# K1921VG1T register map
Vendor: NIIET; Series: K1921VGx; File version: 2.8
CPU: other r0p1, little endian, MPU, FPU, 4 interrupt priority bits
Registers are 32-bit, read-write, reset 0x0 unless marked. A register's access mark holds for its fields unless they carry their own. Offsets are from the block's base; [hi:lo] are bit positions; lines under a group give offsets from that group; {n}, {i} and the like mark numbered series.

## MSC — MSC control registers
Base 0x5201C000
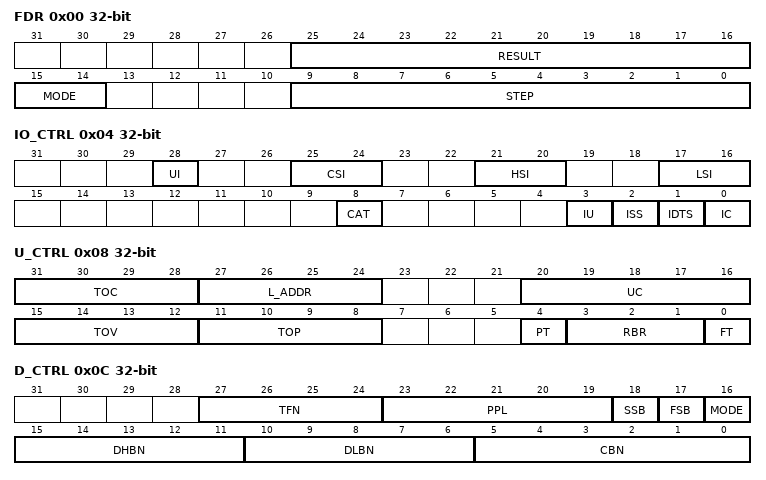
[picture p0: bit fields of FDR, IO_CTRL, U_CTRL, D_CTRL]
0x00 FDR — Fractional divider register
  [25:16] RESULT ro — Count frequency divider
  [15:14] MODE — Mode setting of the frequency divider
    0=TURN_OFF (Divider is turned off. Fmsc isn't generated); 1=NORMAL (Normal divider mod is selected); 2=FRACTIONAL (Fractional divider mode is selected); 3=BYPASS (Bypass mode is selected (Fmsc = Fapb / 2))
  [9:0] STEP — Divider start value in the normal mode / Step of divider in the fractional mode
0x04 IO_CTRL — Input/output Control Register
  [28] UI — Upstream input Index
  [25:24] CSI — Command Slave Index
  [21:20] HSI — High data part Slave Index
  [17:16] LSI — Low data part Slave Index
  [8] CAT — Clock All Time
  [3] IU — Invert Upstream input
  [2] ISS — Invert Slave Select output
  [1] IDTS — Invert Data To Slave output
  [0] IC — Invert Clock output
0x08 U_CTRL — Upstream Control/Status Register
  [31:28] TOC ro — Upstream time out timer counter current value
  [27:24] L_ADDR ro — Last received frame address
  [20:16] UC ro — Upstream bits down counter
  [15:12] TOV — Upstream time out timer restart value
  [11:8] TOP — Upstream time out timer prescaler of receive baud rate frequency (Fbr)
    0=TURN_OFF (Upstream timer prescaler disabled); 1=DIV1 (Fbr/1); 2=DIV2 (Fbr/2); 3=DIV4 (Fbr/4); 4=DIV8 (Fbr/8); 5=DIV16 (Fbr/16); 6=DIV32 (Fbr/32); 7=DIV64 (Fbr/64); 8=DIV128 (Fbr/128); 9=DIV256 (Fbr/256); 10=DIV512 (Fbr/512); 11=DIV1024 (Fbr/1024); 12=DIV2048 (Fbr/2048); 13=DIV4096 (Fbr/4096); 14=DIV8192 (Fbr/8192); 15=DIV16384 (Fbr/16384)
  [4] PT — Parity type (0 - Even parity; 1 - Odd parity)
    0=EVEN (Even parity mode - a parity bit is set on an odd number of 1s in the serial address/data stream); 1=ODD (Odd parity mode - a parity bit is set on an even number of 1s in the serial address/data stream)
  [3:1] RBR — Upstream Channel Receiving Rate
    0=TURN_OFF (Upstream channel disabled); 1=DIV4 (Baud rate = Fmsc/4); 2=DIV8 (Baud rate = Fmsc/8); 3=DIV16 (Baud rate = Fmsc/16); 4=DIV32 (4Baud rate = Fmsc/32); 5=DIV64 (Baud rate = Fmsc/64); 6=DIV128 (Baud rate = Fmsc/128); 7=DIV256 (Baud rate = Fmsc/256)
  [0] FT — Upstream Frame Type (0 - 12-bit; 1 - 16bit)
    0=FRAME_12 (Upstream without 4-bit address field); 1=FRAME_16 (full length 16-bit upstream frame)
0x0C D_CTRL — Downstream Control Register
  [27:24] TFN — passive Time Frames Number
  [23:19] PPL — Passive Phase Length (data/time frame)
  [18] SSB — Second Selection Bit (data/time frame)
  [17] FSB — First Selection Bit (data/time frame)
  [16] MODE — transmission Mode (0 - Triggered; 1 - Data repetition)
    0=TRIGGERED (Triggered mode selected); 1=DATAREPETITION (Data repetition mode selected)
  [15:11] DHBN — Data High Bits Number
  [10:6] DLBN — Data Low Bits Number
  [5:0] CBN — Command Bits Number
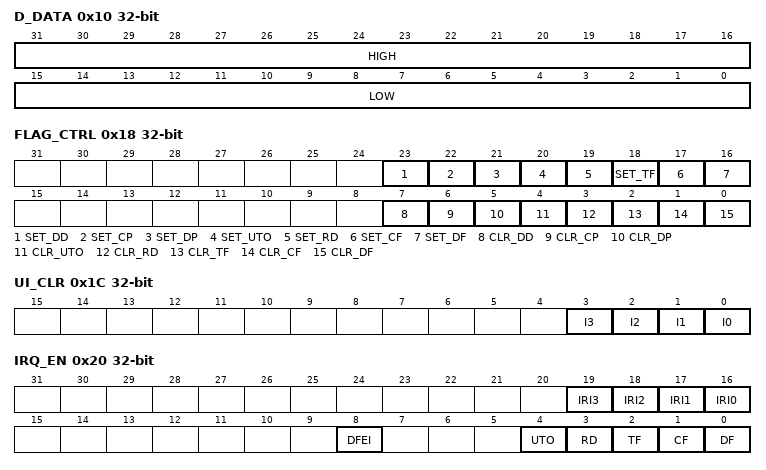
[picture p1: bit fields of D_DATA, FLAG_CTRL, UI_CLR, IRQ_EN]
0x10 D_DATA — Downstream Data bits
  [31:16] HIGH, [15:0] LOW
0x14 D_CMD — Downstream Command bits
  [31:0] VAL
0x18 FLAG_CTRL wo — Flags control register (set/clear)
  [23] SET_DD — Set Downstream Disabled flag
  [22] SET_CP — vCommand pending flag
  [21] SET_DP — Set Data Pending flag
  [20] SET_UTO — Set Upstream Time-Out flag
  [19] SET_RD — Set Receive upstream Data flag
  [18] SET_TF — Set passive Time Frame flag
  [17] SET_CF — Set Command Frame flag
  [16] SET_DF — Set Data Frame flag
  [7] CLR_DD — Clear Downstream Disabled flag
  [6] CLR_CP — Clear Command pending flag
  [5] CLR_DP — Clear Data Pending flag
  [4] CLR_UTO — Clear Upstream Time-Out flag
  [3] CLR_RD — Clear Receive upstream Data flag
  [2] CLR_TF — Clear passive Time Frame flag
  [1] CLR_CF — Clear Command Frame flag
  [0] CLR_DF — Clear Data Frame flag
0x1C UI_CLR wo — Upstream Items valid clear
  [n] I{n} (n=0..3) — Clear valid bit in the Upstream Item {n}
0x20 IRQ_EN — Interrupt requests enable register
  [n+16] IRI{n} (n=0..3) — Ignore Received Item {n}
  [8] DFEI — Data Frame Early Interrupt (after first data bit)
  [4] UTO — enable Upstream Time-Out interrupt
  [3] RD — enable Receive upstream Data interrupt
  [2] TF — enable passive Time Frame interrupt
  [1] CF — enable Command Frame interrupt
  [0] DF — enable Data Frame interrupt
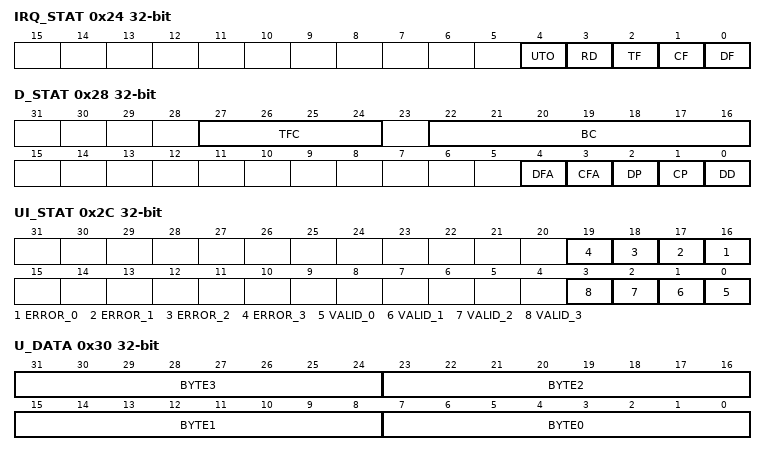
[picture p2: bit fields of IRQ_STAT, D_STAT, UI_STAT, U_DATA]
0x24 IRQ_STAT ro — Interrupt requests status register
  [4] UTO — Upstream Time-Out flag
  [3] RD — Receive upstream Data flag
  [2] TF — passive Time Frame flag
  [1] CF — Command Frame flag
  [0] DF — Data Frame flag
0x28 D_STAT ro — Downstream status register
  [27:24] TFC — passive Time Frames counter
  [22:16] BC — Downstream bits counter
  [4] DFA — Data Frame Active flag
  [3] CFA — Command Frame Active flag
  [2] DP — Data Pending flag
  [1] CP — Command Pending flag
  [0] DD — Downstream Disabled flag
0x2C UI_STAT ro — Upstream items status register
  [n+16] ERROR_{n} (n=0..3) — Item {n} combined error
  [n] VALID_{n} (n=0..3) — Item {n} valid bit
0x30 U_DATA ro — Aggregated upstream items data
  [8n+7:8n] BYTE{n} (n=0..3) — U_ITEM[{n}].DATA byte value
{0x40+4i} U_ITEM[{i}] (i=0..3) group
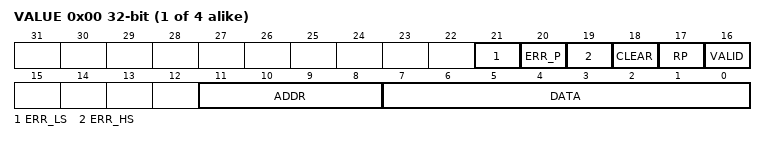
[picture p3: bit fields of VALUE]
  0x00 VALUE — Upstream item index 0
    [21] ERR_LS ro — Error Low Stop bit(s)
    [20] ERR_P ro — Error Parity bit
    [19] ERR_HS ro — Erorr High Start bit
    [18] CLEAR wo — Clear item valit bit
    [17] RP ro — Received Parity bit
    [16] VALID ro — item Valid bit
    [11:8] ADDR ro — Address field
    [7:0] DATA ro
